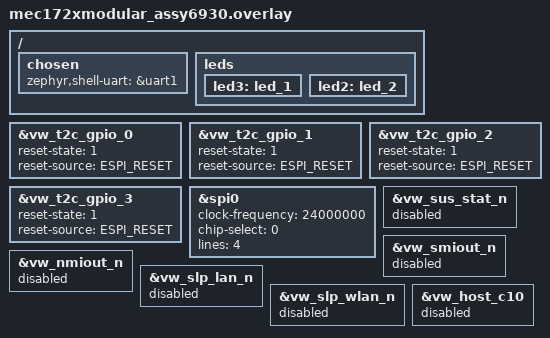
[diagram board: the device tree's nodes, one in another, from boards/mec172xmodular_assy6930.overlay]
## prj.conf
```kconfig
# nothing here

CONFIG_LED=y
CONFIG_REBOOT=y

# console
CONFIG_CONSOLE=y
CONFIG_UART_CONSOLE=y

#SHELL
CONFIG_SHELL=y
CONFIG_GPIO_SHELL=y
CONFIG_LED_SHELL=y
CONFIG_SHELL_PROMPT_UART="MCHP:~$ "
```

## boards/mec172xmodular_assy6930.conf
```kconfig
# eSPI + mec172xevb_assy6906
# CONFIG_ESPI=y
# CONFIG_LOG=y
# CONFIG_LOG_BUFFER_SIZE=4096
# CONFIG_LOG_PROCESS_THREAD_SLEEP_MS=100
# Disable only for this board to check notifications
# CONFIG_ESPI_AUTOMATIC_WARNING_ACKNOWLEDGE=n
# Sample code doesn't handle ACPI host communication
# CONFIG_ESPI_PERIPHERAL_HOST_IO=n
# Test SAF flash portal read/erase/write on EVB
```

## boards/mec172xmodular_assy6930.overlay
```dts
/*
 * Copyright (c) 2020 Intel Corporation
 *
 * SPDX-License-Identifier: Apache-2.0
 */


/ {
	chosen {
		zephyr,shell-uart = &uart1;
	};

	leds {
		led3: led_1 {
			status = "okay";
		};
		led2: led_2 {
			status = "okay";
		};
	};
};

/* Enable Target to Controller Virtual Wires GPIO 0 - 3 */
&vw_t2c_gpio_0 {
	status = "okay";
	reset-state = "1";
	reset-source = "ESPI_RESET";
};

&vw_t2c_gpio_1 {
	status = "okay";
	reset-state = "1";
	reset-source = "ESPI_RESET";
};

&vw_t2c_gpio_2 {
	status = "okay";
	reset-state = "1";
	reset-source = "ESPI_RESET";
};

&vw_t2c_gpio_3 {
	status = "okay";
	reset-state = "1";
	reset-source = "ESPI_RESET";
};

&spi0 {
	status = "okay";
	clock-frequency = <24000000>;
	chip-select = <0>;
	lines = <4>;
};

/* Disable unwanted VWs notifications
 * Refer to include/zephyr/drivers/espi.h
 */
&vw_sus_stat_n {
	status = "disabled";
};

&vw_smiout_n {
	status = "disabled";
};

&vw_nmiout_n {
	status = "disabled";
};

&vw_slp_lan_n {
	status = "disabled";
};

&vw_slp_wlan_n {
	status = "disabled";
};

&vw_host_c10 {
	status = "disabled";
};
```

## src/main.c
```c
/*
 * Copyright (c) 2012-2014 Wind River Systems, Inc.
 *
 * SPDX-License-Identifier: Apache-2.0
 */

/* 1000 msec = 1 sec */
#define SLEEP_TIME_MS   1000

/* The devicetree node identifier for the "led0" alias. */
#define LED1_NODE DT_ALIAS(led1)

#include <stdio.h>
#include <zephyr/kernel.h>
#include <zephyr/drivers/gpio.h>

/*
 * A build error on this line means your board is unsupported.
 * See the sample documentation for information on how to fix this.
 */
static const struct gpio_dt_spec led1 = GPIO_DT_SPEC_GET(LED1_NODE, gpios);

int main(void)
{
	printf("Hello World! %s\n", CONFIG_BOARD_TARGET);

	if (!gpio_is_ready_dt(&led1)) {
		return 0;
	}

	int ret = gpio_pin_configure_dt(&led1, GPIO_OUTPUT_ACTIVE);
	if (ret < 0) {
		return 0;
	}

	while(1) {
		gpio_pin_set_dt(&led1, 0);
		k_msleep(SLEEP_TIME_MS);

		gpio_pin_set_dt(&led1, 1);
		k_msleep(SLEEP_TIME_MS);
	}

	return 0;
}
```
